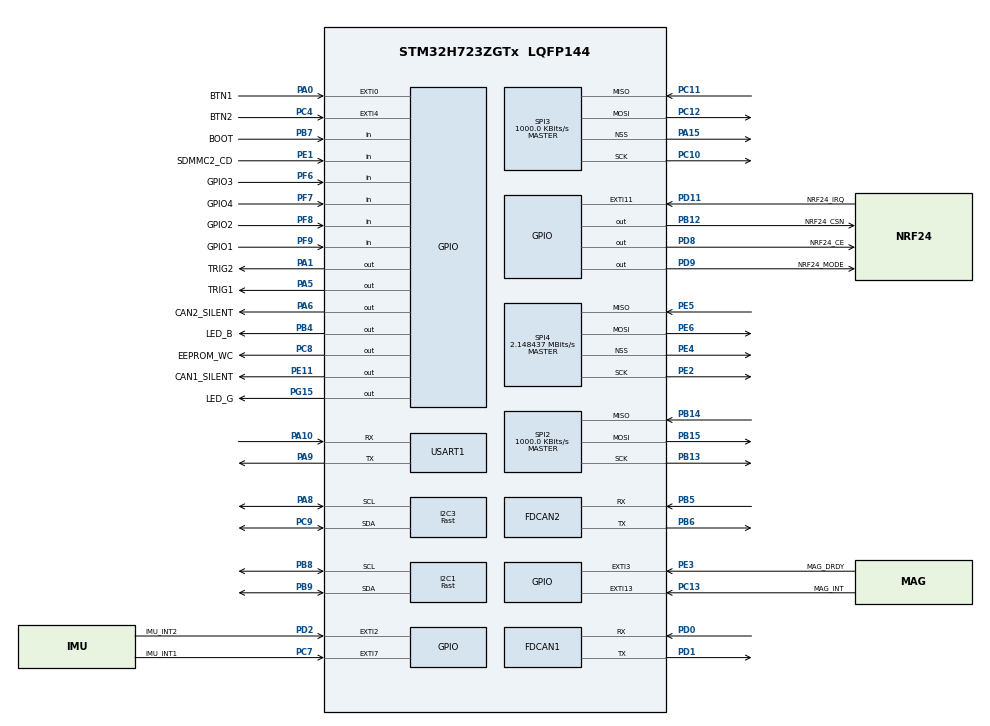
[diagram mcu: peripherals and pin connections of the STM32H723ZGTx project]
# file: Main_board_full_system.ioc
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CORTEX_M7.CPU_DCache=Enabled
CORTEX_M7.CPU_ICache=Enabled
CORTEX_M7.default_mode_Activation=1
FDCAN1.CalculateBaudRateNominal=1250000
FDCAN1.CalculateTimeBitNominal=800
FDCAN1.CalculateTimeQuantumNominal=160.0
FDCAN2.CalculateBaudRateNominal=125000
FDCAN2.CalculateTimeBitNominal=8000
FDCAN2.CalculateTimeQuantumNominal=500.0
FDCAN2.NominalPrescaler=50
FDCAN2.NominalTimeSeg1=13
FREERTOS.Tasks01=debugTask,24,512,startDebugTask,Default,NULL,Static,debugTaskBuffer,debugTaskControlBlock;radioTask,32,512,startRadioTask,As external,NULL,Static,radioTaskBuffer,radioTaskControlBlock;motorTask,40,512,startMotorTask,As external,NULL,Static,motorTaskBuffer,motorTaskControlBlock;sensorsTask,8,512,startSensorsTask,As external,NULL,Static,sensorsTaskBuffer,sensorsTaskControlBlock
FREERTOS.configMINIMAL_STACK_SIZE=512
FREERTOS.configUSE_NEWLIB_REENTRANT=1
I2C1.CustomTiming=Enabled
I2C1.I2C_Speed_Mode=I2C_Fast
I2C1.Speed=100
I2C1.Timing=0x60100AB6
I2C3.I2C_Speed_Mode=I2C_Fast
I2C3.Timing=0x60100AB6
Mcu.Family=STM32H7
Mcu.Name=STM32H723ZGTx
Mcu.Package=LQFP144
NVIC.FDCAN1_IT0_IRQn=true\:5\:0\:false\:false\:true\:true\:true\:true\:true
NVIC.FDCAN1_IT1_IRQn=true\:5\:0\:false\:false\:true\:true\:true\:true\:true
NVIC.FDCAN2_IT0_IRQn=true\:5\:0\:false\:false\:true\:true\:true\:true\:true
NVIC.FDCAN2_IT1_IRQn=true\:5\:0\:false\:false\:true\:true\:true\:true\:true
NVIC.I2C1_EV_IRQn=true\:5\:0\:false\:false\:true\:true\:true\:true\:true
NVIC.I2C3_EV_IRQn=true\:5\:0\:false\:false\:true\:true\:true\:true\:true
NVIC.PriorityGroup=NVIC_PRIORITYGROUP_4
NVIC.SPI2_IRQn=true\:5\:0\:false\:false\:true\:true\:true\:true\:true
NVIC.SPI3_IRQn=true\:5\:0\:false\:false\:true\:true\:true\:true\:true
NVIC.SPI4_IRQn=true\:5\:0\:false\:false\:true\:true\:true\:true\:true
NVIC.TIM6_DAC_IRQn=true\:15\:0\:false\:false\:true\:false\:false\:true\:true
NVIC.TimeBase=TIM6_DAC_IRQn
NVIC.TimeBaseIP=TIM6
NVIC.USART1_IRQn=true\:5\:0\:false\:false\:true\:true\:true\:true\:true
PA0.GPIO_Label=BTN1
PA0.Signal=GPXTI0
PA1.GPIO_Label=TRIG2
PA1.Signal=GPIO_Output
PA10.Mode=Asynchronous
PA10.Signal=USART1_RX
PA11.Signal=USB_OTG_HS_DM
PA12.Signal=USB_OTG_HS_DP
PA13(JTMS/SWDIO).Mode=Trace_Asynchronous_SW
PA13(JTMS/SWDIO).Signal=DEBUG_JTMS-SWDIO
PA14(JTCK/SWCLK).Mode=Trace_Asynchronous_SW
PA14(JTCK/SWCLK).Signal=DEBUG_JTCK-SWCLK
PA15(JTDI).Mode=NSS_Signal_Hard_Output
PA15(JTDI).Signal=SPI3_NSS
PA5.GPIO_Label=TRIG1
PA5.Signal=GPIO_Output
PA6.GPIO_Label=CAN2_SILENT
PA6.GPIO_PuPd=GPIO_PULLUP
PA6.Signal=GPIO_Output
PA8.Mode=I2C
PA8.Signal=I2C3_SCL
PA9.Mode=Asynchronous
PA9.Signal=USART1_TX
PB12.GPIO_Label=NRF24_CSN
PB12.Signal=GPIO_Output
PB13.Mode=Full_Duplex_Master
PB13.Signal=SPI2_SCK
PB14.Mode=Full_Duplex_Master
PB14.Signal=SPI2_MISO
PB15.Mode=Full_Duplex_Master
PB15.Signal=SPI2_MOSI
PB3(JTDO/TRACESWO).Mode=Trace_Asynchronous_SW
PB3(JTDO/TRACESWO).Signal=DEBUG_JTDO-SWO
PB4(NJTRST).GPIO_Label=LED_B
PB4(NJTRST).Signal=GPIO_Output
PB5.Mode=FDCAN_Activate
PB5.Signal=FDCAN2_RX
PB6.Mode=FDCAN_Activate
PB6.Signal=FDCAN2_TX
PB7.GPIO_Label=BOOT
PB7.Signal=GPIO_Input
PB8.Mode=I2C
PB8.Signal=I2C1_SCL
PB9.Mode=I2C
PB9.Signal=I2C1_SDA
PC10.Mode=Full_Duplex_Master
PC10.Signal=SPI3_SCK
PC11.Mode=Full_Duplex_Master
PC11.Signal=SPI3_MISO
PC12.Mode=Full_Duplex_Master
PC12.Signal=SPI3_MOSI
PC13.GPIO_Label=MAG_INT
PC13.Signal=GPXTI13
PC14-OSC32_IN.Mode=LSE-External-Clock-Source
PC14-OSC32_IN.Signal=RCC_OSC32_IN
PC4.GPIO_Label=BTN2
PC4.Signal=GPXTI4
PC7.GPIO_Label=IMU_INT1
PC7.Signal=GPXTI7
PC8.GPIO_Label=EEPROM_WC
PC8.GPIO_PuPd=GPIO_PULLUP
PC8.Signal=GPIO_Output
PC9.Mode=I2C
PC9.Signal=I2C3_SDA
PD0.Mode=FDCAN_Activate
PD0.Signal=FDCAN1_RX
PD1.Mode=FDCAN_Activate
PD1.Signal=FDCAN1_TX
PD11.GPIO_Label=NRF24_IRQ
PD11.Signal=GPXTI11
PD2.GPIO_Label=IMU_INT2
PD2.Signal=GPXTI2
PD6.Signal=SDMMC2_CK
PD7.Signal=SDMMC2_CMD
PD8.GPIO_Label=NRF24_CE
PD8.Signal=GPIO_Output
PD9.GPIO_Label=NRF24_MODE
PD9.Signal=GPIO_Output
PE1.GPIO_Label=SDMMC2_CD
PE1.Signal=GPIO_Input
PE11.GPIO_Label=CAN1_SILENT
PE11.GPIO_PuPd=GPIO_PULLUP
PE11.Signal=GPIO_Output
PE2.Mode=Full_Duplex_Master
PE2.Signal=SPI4_SCK
PE3.GPIO_Label=MAG_DRDY
PE3.Signal=GPXTI3
PE4.Mode=NSS_Signal_Hard_Output
PE4.Signal=SPI4_NSS
PE5.Mode=Full_Duplex_Master
PE5.Signal=SPI4_MISO
PE6.Mode=Full_Duplex_Master
PE6.Signal=SPI4_MOSI
PF6.GPIO_Label=GPIO3
PF6.Signal=GPIO_Input
PF7.GPIO_Label=GPIO4
PF7.Signal=GPIO_Input
PF8.GPIO_Label=GPIO2
PF8.Signal=GPIO_Input
PF9.GPIO_Label=GPIO1
PF9.Signal=GPIO_Input
PG10.Signal=SDMMC2_D1
PG11.Signal=SDMMC2_D2
PG12.Signal=SDMMC2_D3
PG15.GPIO_Label=LED_G
PG15.Signal=GPIO_Output
PG9.Signal=SDMMC2_D0
PH0-OSC_IN.Mode=HSE-External-Clock-Source
PH0-OSC_IN.Signal=RCC_OSC_IN
ProjectManager.HeapSize=0x200
ProjectManager.StackSize=0x400
ProjectManager.TargetToolchain=STM32CubeIDE
RCC.ADCFreq_Value=100000000
RCC.APB1Freq_Value=137500000
RCC.APB2Freq_Value=137500000
RCC.APB3Freq_Value=137500000
RCC.APB4Freq_Value=137500000
RCC.CortexFreq_Value=550000000
RCC.D1PPRE=RCC_APB3_DIV2
RCC.D2PPRE1=RCC_APB1_DIV2
RCC.D2PPRE2=RCC_APB2_DIV2
RCC.D3PPRE=RCC_APB4_DIV2
RCC.DIVM1=2
RCC.DIVM2=2
RCC.DIVM3=5
RCC.DIVN1=44
RCC.DIVN2=16
RCC.DIVN3=64
RCC.DIVP1=1
RCC.DIVP3=5
RCC.DIVQ1=5
RCC.FDCANCLockSelection=RCC_FDCANCLKSOURCE_PLL2
RCC.HCLKFreq_Value=275000000
RCC.HPRE=RCC_HCLK_DIV2
RCC.PLL3FRACN=0
RCC.PLLFRACN=0
RCC.PLLSourceVirtual=RCC_PLLSOURCE_HSE
RCC.SPI123CLockSelection=RCC_SPI123CLKSOURCE_PLL3
RCC.SYSCLKFreq_VALUE=550000000
RCC.SYSCLKSource=RCC_SYSCLKSOURCE_PLLCLK
RCC.USBFreq_Value=110000000
SPI2.BaudRatePrescaler=SPI_BAUDRATEPRESCALER_64
SPI2.CalculateBaudRate=1000.0 KBits/s
SPI2.DataSize=SPI_DATASIZE_8BIT
SPI2.Direction=SPI_DIRECTION_2LINES
SPI2.Mode=SPI_MODE_MASTER
SPI2.VirtualType=VM_MASTER
SPI3.BaudRatePrescaler=SPI_BAUDRATEPRESCALER_64
SPI3.CalculateBaudRate=1000.0 KBits/s
SPI3.DataSize=SPI_DATASIZE_8BIT
SPI3.Direction=SPI_DIRECTION_2LINES
SPI3.Mode=SPI_MODE_MASTER
SPI3.VirtualNSS=VM_NSSHARD
SPI3.VirtualType=VM_MASTER
SPI4.BaudRatePrescaler=SPI_BAUDRATEPRESCALER_64
SPI4.CalculateBaudRate=2.148437 MBits/s
SPI4.DataSize=SPI_DATASIZE_8BIT
SPI4.Direction=SPI_DIRECTION_2LINES
SPI4.Mode=SPI_MODE_MASTER
SPI4.VirtualNSS=VM_NSSHARD
SPI4.VirtualType=VM_MASTER
USART1.VirtualMode-Asynchronous=VM_ASYNC
VP_CRC_VS_CRC.Mode=CRC_Activate
VP_FREERTOS_VS_CMSIS_V2.Mode=CMSIS_V2
VP_RCC_LSE.Mode=CRS SYNC Source LSE
VP_SYS_VS_tim6.Mode=TIM6
board=custom

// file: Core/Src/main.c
/* USER CODE BEGIN Header */
/**
  ******************************************************************************
  * @file           : main.c
  * @brief          : Main program body
  ******************************************************************************
  * @attention
  *
  * Copyright (c) 2024 STMicroelectronics.
  * All rights reserved.
  *
  * This software is licensed under terms that can be found in the LICENSE file
  * in the root directory of this software component.
  * If no LICENSE file comes with this software, it is provided AS-IS.
  *
  ******************************************************************************
  */
/* USER CODE END Header */
#include "main.h"
#include "cmsis_os.h"

/* USER CODE BEGIN Includes */
#include "tasks.h"
/* USER CODE END Includes */

typedef StaticTask_t osStaticThreadDef_t;

CRC_HandleTypeDef hcrc;

FDCAN_HandleTypeDef hfdcan1;
FDCAN_HandleTypeDef hfdcan2;

I2C_HandleTypeDef hi2c1;
I2C_HandleTypeDef hi2c3;

SPI_HandleTypeDef hspi2;
SPI_HandleTypeDef hspi3;
SPI_HandleTypeDef hspi4;

UART_HandleTypeDef huart1;

/* Definitions for debugTask */
osThreadId_t debugTaskHandle;
uint32_t debugTaskBuffer[ 512 ];
osStaticThreadDef_t debugTaskControlBlock;
const osThreadAttr_t debugTask_attributes = {
  .name = "debugTask",
  .cb_mem = &debugTaskControlBlock,
  .cb_size = sizeof(debugTaskControlBlock),
  .stack_mem = &debugTaskBuffer[0],
  .stack_size = sizeof(debugTaskBuffer),
  .priority = (osPriority_t) osPriorityNormal,
};
/* Definitions for radioTask */
osThreadId_t radioTaskHandle;
uint32_t radioTaskBuffer[ 512 ];
osStaticThreadDef_t radioTaskControlBlock;
const osThreadAttr_t radioTask_attributes = {
  .name = "radioTask",
  .cb_mem = &radioTaskControlBlock,
  .cb_size = sizeof(radioTaskControlBlock),
  .stack_mem = &radioTaskBuffer[0],
  .stack_size = sizeof(radioTaskBuffer),
  .priority = (osPriority_t) osPriorityAboveNormal,
};
/* Definitions for motorTask */
osThreadId_t motorTaskHandle;
uint32_t motorTaskBuffer[ 512 ];
osStaticThreadDef_t motorTaskControlBlock;
const osThreadAttr_t motorTask_attributes = {
  .name = "motorTask",
  .cb_mem = &motorTaskControlBlock,
  .cb_size = sizeof(motorTaskControlBlock),
  .stack_mem = &motorTaskBuffer[0],
  .stack_size = sizeof(motorTaskBuffer),
  .priority = (osPriority_t) osPriorityHigh,
};
/* Definitions for sensorsTask */
osThreadId_t sensorsTaskHandle;
uint32_t sensorsTaskBuffer[ 512 ];
osStaticThreadDef_t sensorsTaskControlBlock;
const osThreadAttr_t sensorsTask_attributes = {
  .name = "sensorsTask",
  .cb_mem = &sensorsTaskControlBlock,
  .cb_size = sizeof(sensorsTaskControlBlock),
  .stack_mem = &sensorsTaskBuffer[0],
  .stack_size = sizeof(sensorsTaskBuffer),
  .priority = (osPriority_t) osPriorityLow,
};

void SystemClock_Config(void);
void PeriphCommonClock_Config(void);
static void MPU_Config(void);
static void MX_GPIO_Init(void);
static void MX_FDCAN1_Init(void);
static void MX_FDCAN2_Init(void);
static void MX_I2C1_Init(void);
static void MX_I2C3_Init(void);
static void MX_SPI2_Init(void);
static void MX_SPI3_Init(void);
static void MX_SPI4_Init(void);
static void MX_USART1_UART_Init(void);
static void MX_CRC_Init(void);
void startDebugTask(void *argument);
extern void startRadioTask(void *argument);
extern void startMotorTask(void *argument);
extern void startSensorsTask(void *argument);

int main(void)
{

  /* MPU Configuration--------------------------------------------------------*/
  MPU_Config();
/* Enable the CPU Cache */

  /* Enable I-Cache---------------------------------------------------------*/
  SCB_EnableICache();

  /* Enable D-Cache---------------------------------------------------------*/
  SCB_EnableDCache();

  /* MCU Configuration--------------------------------------------------------*/

  /* Reset of all peripherals, Initializes the Flash interface and the Systick. */
  HAL_Init();

  /* Configure the system clock */
  SystemClock_Config();

/* Configure the peripherals common clocks */
  PeriphCommonClock_Config();

  /* Initialize all configured peripherals */
  MX_GPIO_Init();
  MX_FDCAN1_Init();
  MX_FDCAN2_Init();
  MX_I2C1_Init();
  MX_I2C3_Init();
  MX_SPI2_Init();
  MX_SPI3_Init();
  MX_SPI4_Init();
  MX_USART1_UART_Init();
  MX_CRC_Init();

  /* Init scheduler */
  osKernelInitialize();

  /* Create the thread(s) */
  /* creation of debugTask */
  debugTaskHandle = osThreadNew(startDebugTask, NULL, &debugTask_attributes);

  /* creation of radioTask */
  radioTaskHandle = osThreadNew(startRadioTask, NULL, &radioTask_attributes);

  /* creation of motorTask */
  motorTaskHandle = osThreadNew(startMotorTask, NULL, &motorTask_attributes);

  /* creation of sensorsTask */
  sensorsTaskHandle = osThreadNew(startSensorsTask, NULL, &sensorsTask_attributes);

  /* Start scheduler */
  osKernelStart();

  /* We should never get here as control is now taken by the scheduler */
  /* Infinite loop */
  while (1)
  {

  }
}

void SystemClock_Config(void)
{
  RCC_OscInitTypeDef RCC_OscInitStruct = {0};
  RCC_ClkInitTypeDef RCC_ClkInitStruct = {0};
  RCC_CRSInitTypeDef RCC_CRSInitStruct = {0};

  /** Supply configuration update enable
  */
  HAL_PWREx_ConfigSupply(PWR_LDO_SUPPLY);

  /** Configure the main internal regulator output voltage
  */
  __HAL_PWR_VOLTAGESCALING_CONFIG(PWR_REGULATOR_VOLTAGE_SCALE0);

  while(!__HAL_PWR_GET_FLAG(PWR_FLAG_VOSRDY)) {}

  /** Initializes the RCC Oscillators according to the specified parameters
  * in the RCC_OscInitTypeDef structure.
  */
  RCC_OscInitStruct.OscillatorType = RCC_OSCILLATORTYPE_HSI48|RCC_OSCILLATORTYPE_HSE
                              |RCC_OSCILLATORTYPE_LSE;
  RCC_OscInitStruct.HSEState = RCC_HSE_BYPASS;
  RCC_OscInitStruct.LSEState = RCC_LSE_BYPASS;
  RCC_OscInitStruct.HSI48State = RCC_HSI48_ON;
  RCC_OscInitStruct.PLL.PLLState = RCC_PLL_ON;
  RCC_OscInitStruct.PLL.PLLSource = RCC_PLLSOURCE_HSE;
  RCC_OscInitStruct.PLL.PLLM = 2;
  RCC_OscInitStruct.PLL.PLLN = 44;
  RCC_OscInitStruct.PLL.PLLP = 1;
  RCC_OscInitStruct.PLL.PLLQ = 5;
  RCC_OscInitStruct.PLL.PLLR = 2;
  RCC_OscInitStruct.PLL.PLLRGE = RCC_PLL1VCIRANGE_3;
  RCC_OscInitStruct.PLL.PLLVCOSEL = RCC_PLL1VCOWIDE;
  RCC_OscInitStruct.PLL.PLLFRACN = 0;
  if (HAL_RCC_OscConfig(&RCC_OscInitStruct) != HAL_OK)
  {
    Error_Handler();
  }

  /** Initializes the CPU, AHB and APB buses clocks
  */
  RCC_ClkInitStruct.ClockType = RCC_CLOCKTYPE_HCLK|RCC_CLOCKTYPE_SYSCLK
                              |RCC_CLOCKTYPE_PCLK1|RCC_CLOCKTYPE_PCLK2
                              |RCC_CLOCKTYPE_D3PCLK1|RCC_CLOCKTYPE_D1PCLK1;
  RCC_ClkInitStruct.SYSCLKSource = RCC_SYSCLKSOURCE_PLLCLK;
  RCC_ClkInitStruct.SYSCLKDivider = RCC_SYSCLK_DIV1;
  RCC_ClkInitStruct.AHBCLKDivider = RCC_HCLK_DIV2;
  RCC_ClkInitStruct.APB3CLKDivider = RCC_APB3_DIV2;
  RCC_ClkInitStruct.APB1CLKDivider = RCC_APB1_DIV2;
  RCC_ClkInitStruct.APB2CLKDivider = RCC_APB2_DIV2;
  RCC_ClkInitStruct.APB4CLKDivider = RCC_APB4_DIV2;

  if (HAL_RCC_ClockConfig(&RCC_ClkInitStruct, FLASH_LATENCY_3) != HAL_OK)
  {
    Error_Handler();
  }

  /** Enable the SYSCFG APB clock
  */
  __HAL_RCC_CRS_CLK_ENABLE();

  /** Configures CRS
  */
  RCC_CRSInitStruct.Prescaler = RCC_CRS_SYNC_DIV1;
  RCC_CRSInitStruct.Source = RCC_CRS_SYNC_SOURCE_LSE;
  RCC_CRSInitStruct.Polarity = RCC_CRS_SYNC_POLARITY_RISING;
  RCC_CRSInitStruct.ReloadValue = __HAL_RCC_CRS_RELOADVALUE_CALCULATE(48000000,32768);
  RCC_CRSInitStruct.ErrorLimitValue = 34;
  RCC_CRSInitStruct.HSI48CalibrationValue = 32;

  HAL_RCCEx_CRSConfig(&RCC_CRSInitStruct);
}

void PeriphCommonClock_Config(void)
{
  RCC_PeriphCLKInitTypeDef PeriphClkInitStruct = {0};

  /** Initializes the peripherals clock
  */
  PeriphClkInitStruct.PeriphClockSelection = RCC_PERIPHCLK_SPI3|RCC_PERIPHCLK_SPI2
                              |RCC_PERIPHCLK_FDCAN;
  PeriphClkInitStruct.PLL2.PLL2M = 2;
  PeriphClkInitStruct.PLL2.PLL2N = 16;
  PeriphClkInitStruct.PLL2.PLL2P = 2;
  PeriphClkInitStruct.PLL2.PLL2Q = 2;
  PeriphClkInitStruct.PLL2.PLL2R = 2;
  PeriphClkInitStruct.PLL2.PLL2RGE = RCC_PLL2VCIRANGE_3;
  PeriphClkInitStruct.PLL2.PLL2VCOSEL = RCC_PLL2VCOWIDE;
  PeriphClkInitStruct.PLL2.PLL2FRACN = 0;
  PeriphClkInitStruct.PLL3.PLL3M = 5;
  PeriphClkInitStruct.PLL3.PLL3N = 64;
  PeriphClkInitStruct.PLL3.PLL3P = 5;
  PeriphClkInitStruct.PLL3.PLL3Q = 2;
  PeriphClkInitStruct.PLL3.PLL3R = 2;
  PeriphClkInitStruct.PLL3.PLL3RGE = RCC_PLL3VCIRANGE_2;
  PeriphClkInitStruct.PLL3.PLL3VCOSEL = RCC_PLL3VCOWIDE;
  PeriphClkInitStruct.PLL3.PLL3FRACN = 0;
  PeriphClkInitStruct.Spi123ClockSelection = RCC_SPI123CLKSOURCE_PLL3;
  PeriphClkInitStruct.FdcanClockSelection = RCC_FDCANCLKSOURCE_PLL2;
  if (HAL_RCCEx_PeriphCLKConfig(&PeriphClkInitStruct) != HAL_OK)
  {
    Error_Handler();
  }
}

static void MX_CRC_Init(void)
{

  hcrc.Instance = CRC;
  hcrc.Init.DefaultPolynomialUse = DEFAULT_POLYNOMIAL_ENABLE;
  hcrc.Init.DefaultInitValueUse = DEFAULT_INIT_VALUE_ENABLE;
  hcrc.Init.InputDataInversionMode = CRC_INPUTDATA_INVERSION_NONE;
  hcrc.Init.OutputDataInversionMode = CRC_OUTPUTDATA_INVERSION_DISABLE;
  hcrc.InputDataFormat = CRC_INPUTDATA_FORMAT_BYTES;
  if (HAL_CRC_Init(&hcrc) != HAL_OK)
  {
    Error_Handler();
  }

}

static void MX_FDCAN1_Init(void)
{

  hfdcan1.Instance = FDCAN1;
  hfdcan1.Init.FrameFormat = FDCAN_FRAME_CLASSIC;
  hfdcan1.Init.Mode = FDCAN_MODE_NORMAL;
  hfdcan1.Init.AutoRetransmission = DISABLE;
  hfdcan1.Init.TransmitPause = DISABLE;
  hfdcan1.Init.ProtocolException = DISABLE;
  hfdcan1.Init.NominalPrescaler = 16;
  hfdcan1.Init.NominalSyncJumpWidth = 1;
  hfdcan1.Init.NominalTimeSeg1 = 2;
  hfdcan1.Init.NominalTimeSeg2 = 2;
  hfdcan1.Init.DataPrescaler = 1;
  hfdcan1.Init.DataSyncJumpWidth = 1;
  hfdcan1.Init.DataTimeSeg1 = 1;
  hfdcan1.Init.DataTimeSeg2 = 1;
  hfdcan1.Init.MessageRAMOffset = 0;
  hfdcan1.Init.StdFiltersNbr = 0;
  hfdcan1.Init.ExtFiltersNbr = 0;
  hfdcan1.Init.RxFifo0ElmtsNbr = 0;
  hfdcan1.Init.RxFifo0ElmtSize = FDCAN_DATA_BYTES_8;
  hfdcan1.Init.RxFifo1ElmtsNbr = 0;
  hfdcan1.Init.RxFifo1ElmtSize = FDCAN_DATA_BYTES_8;
  hfdcan1.Init.RxBuffersNbr = 0;
  hfdcan1.Init.RxBufferSize = FDCAN_DATA_BYTES_8;
  hfdcan1.Init.TxEventsNbr = 0;
  hfdcan1.Init.TxBuffersNbr = 0;
  hfdcan1.Init.TxFifoQueueElmtsNbr = 0;
  hfdcan1.Init.TxFifoQueueMode = FDCAN_TX_FIFO_OPERATION;
  hfdcan1.Init.TxElmtSize = FDCAN_DATA_BYTES_8;
  if (HAL_FDCAN_Init(&hfdcan1) != HAL_OK)
  {
    Error_Handler();
  }

}

static void MX_FDCAN2_Init(void)
{

  hfdcan2.Instance = FDCAN2;
  hfdcan2.Init.FrameFormat = FDCAN_FRAME_CLASSIC;
  hfdcan2.Init.Mode = FDCAN_MODE_NORMAL;
  hfdcan2.Init.AutoRetransmission = DISABLE;
  hfdcan2.Init.TransmitPause = DISABLE;
  hfdcan2.Init.ProtocolException = DISABLE;
  hfdcan2.Init.NominalPrescaler = 50;
  hfdcan2.Init.NominalSyncJumpWidth = 1;
  hfdcan2.Init.NominalTimeSeg1 = 13;
  hfdcan2.Init.NominalTimeSeg2 = 2;
  hfdcan2.Init.DataPrescaler = 1;
  hfdcan2.Init.DataSyncJumpWidth = 1;
  hfdcan2.Init.DataTimeSeg1 = 1;
  hfdcan2.Init.DataTimeSeg2 = 1;
  hfdcan2.Init.MessageRAMOffset = 0;
  hfdcan2.Init.StdFiltersNbr = 0;
  hfdcan2.Init.ExtFiltersNbr = 0;
  hfdcan2.Init.RxFifo0ElmtsNbr = 0;
  hfdcan2.Init.RxFifo0ElmtSize = FDCAN_DATA_BYTES_8;
  hfdcan2.Init.RxFifo1ElmtsNbr = 0;
  hfdcan2.Init.RxFifo1ElmtSize = FDCAN_DATA_BYTES_8;
  hfdcan2.Init.RxBuffersNbr = 0;
  hfdcan2.Init.RxBufferSize = FDCAN_DATA_BYTES_8;
  hfdcan2.Init.TxEventsNbr = 0;
  hfdcan2.Init.TxBuffersNbr = 0;
  hfdcan2.Init.TxFifoQueueElmtsNbr = 0;
  hfdcan2.Init.TxFifoQueueMode = FDCAN_TX_FIFO_OPERATION;
  hfdcan2.Init.TxElmtSize = FDCAN_DATA_BYTES_8;
  if (HAL_FDCAN_Init(&hfdcan2) != HAL_OK)
  {
    Error_Handler();
  }

}

static void MX_I2C1_Init(void)
{

  hi2c1.Instance = I2C1;
  hi2c1.Init.Timing = 0x60100AB6;
  hi2c1.Init.OwnAddress1 = 0;
  hi2c1.Init.AddressingMode = I2C_ADDRESSINGMODE_7BIT;
  hi2c1.Init.DualAddressMode = I2C_DUALADDRESS_DISABLE;
  hi2c1.Init.OwnAddress2 = 0;
  hi2c1.Init.OwnAddress2Masks = I2C_OA2_NOMASK;
  hi2c1.Init.GeneralCallMode = I2C_GENERALCALL_DISABLE;
  hi2c1.Init.NoStretchMode = I2C_NOSTRETCH_DISABLE;
  if (HAL_I2C_Init(&hi2c1) != HAL_OK)
  {
    Error_Handler();
  }

  /** Configure Analogue filter
  */
  if (HAL_I2CEx_ConfigAnalogFilter(&hi2c1, I2C_ANALOGFILTER_ENABLE) != HAL_OK)
  {
    Error_Handler();
  }

  /** Configure Digital filter
  */
  if (HAL_I2CEx_ConfigDigitalFilter(&hi2c1, 0) != HAL_OK)
  {
    Error_Handler();
  }

}

static void MX_I2C3_Init(void)
{

  hi2c3.Instance = I2C3;
  hi2c3.Init.Timing = 0x60100AB6;
  hi2c3.Init.OwnAddress1 = 0;
  hi2c3.Init.AddressingMode = I2C_ADDRESSINGMODE_7BIT;
  hi2c3.Init.DualAddressMode = I2C_DUALADDRESS_DISABLE;
  hi2c3.Init.OwnAddress2 = 0;
  hi2c3.Init.OwnAddress2Masks = I2C_OA2_NOMASK;
  hi2c3.Init.GeneralCallMode = I2C_GENERALCALL_DISABLE;
  hi2c3.Init.NoStretchMode = I2C_NOSTRETCH_DISABLE;
  if (HAL_I2C_Init(&hi2c3) != HAL_OK)
  {
    Error_Handler();
  }

  /** Configure Analogue filter
  */
  if (HAL_I2CEx_ConfigAnalogFilter(&hi2c3, I2C_ANALOGFILTER_ENABLE) != HAL_OK)
  {
    Error_Handler();
  }

  /** Configure Digital filter
  */
  if (HAL_I2CEx_ConfigDigitalFilter(&hi2c3, 0) != HAL_OK)
  {
    Error_Handler();
  }

}

static void MX_SPI2_Init(void)
{

  /* SPI2 parameter configuration*/
  hspi2.Instance = SPI2;
  hspi2.Init.Mode = SPI_MODE_MASTER;
  hspi2.Init.Direction = SPI_DIRECTION_2LINES;
  hspi2.Init.DataSize = SPI_DATASIZE_8BIT;
  hspi2.Init.CLKPolarity = SPI_POLARITY_LOW;
  hspi2.Init.CLKPhase = SPI_PHASE_1EDGE;
  hspi2.Init.NSS = SPI_NSS_SOFT;
  hspi2.Init.BaudRatePrescaler = SPI_BAUDRATEPRESCALER_64;
  hspi2.Init.FirstBit = SPI_FIRSTBIT_MSB;
  hspi2.Init.TIMode = SPI_TIMODE_DISABLE;
  hspi2.Init.CRCCalculation = SPI_CRCCALCULATION_DISABLE;
  hspi2.Init.CRCPolynomial = 0x0;
  hspi2.Init.NSSPMode = SPI_NSS_PULSE_ENABLE;
  hspi2.Init.NSSPolarity = SPI_NSS_POLARITY_LOW;
  hspi2.Init.FifoThreshold = SPI_FIFO_THRESHOLD_01DATA;
  hspi2.Init.TxCRCInitializationPattern = SPI_CRC_INITIALIZATION_ALL_ZERO_PATTERN;
  hspi2.Init.RxCRCInitializationPattern = SPI_CRC_INITIALIZATION_ALL_ZERO_PATTERN;
  hspi2.Init.MasterSSIdleness = SPI_MASTER_SS_IDLENESS_00CYCLE;
  hspi2.Init.MasterInterDataIdleness = SPI_MASTER_INTERDATA_IDLENESS_00CYCLE;
  hspi2.Init.MasterReceiverAutoSusp = SPI_MASTER_RX_AUTOSUSP_DISABLE;
  hspi2.Init.MasterKeepIOState = SPI_MASTER_KEEP_IO_STATE_DISABLE;
  hspi2.Init.IOSwap = SPI_IO_SWAP_DISABLE;
  if (HAL_SPI_Init(&hspi2) != HAL_OK)
  {
    Error_Handler();
  }

}

static void MX_SPI3_Init(void)
{

  /* SPI3 parameter configuration*/
  hspi3.Instance = SPI3;
  hspi3.Init.Mode = SPI_MODE_MASTER;
  hspi3.Init.Direction = SPI_DIRECTION_2LINES;
  hspi3.Init.DataSize = SPI_DATASIZE_8BIT;
  hspi3.Init.CLKPolarity = SPI_POLARITY_LOW;
  hspi3.Init.CLKPhase = SPI_PHASE_1EDGE;
  hspi3.Init.NSS = SPI_NSS_HARD_OUTPUT;
  hspi3.Init.BaudRatePrescaler = SPI_BAUDRATEPRESCALER_64;
  hspi3.Init.FirstBit = SPI_FIRSTBIT_MSB;
  hspi3.Init.TIMode = SPI_TIMODE_DISABLE;
  hspi3.Init.CRCCalculation = SPI_CRCCALCULATION_DISABLE;
  hspi3.Init.CRCPolynomial = 0x0;
  hspi3.Init.NSSPMode = SPI_NSS_PULSE_ENABLE;
  hspi3.Init.NSSPolarity = SPI_NSS_POLARITY_LOW;
  hspi3.Init.FifoThreshold = SPI_FIFO_THRESHOLD_01DATA;
  hspi3.Init.TxCRCInitializationPattern = SPI_CRC_INITIALIZATION_ALL_ZERO_PATTERN;
  hspi3.Init.RxCRCInitializationPattern = SPI_CRC_INITIALIZATION_ALL_ZERO_PATTERN;
  hspi3.Init.MasterSSIdleness = SPI_MASTER_SS_IDLENESS_00CYCLE;
  hspi3.Init.MasterInterDataIdleness = SPI_MASTER_INTERDATA_IDLENESS_00CYCLE;
  hspi3.Init.MasterReceiverAutoSusp = SPI_MASTER_RX_AUTOSUSP_DISABLE;
  hspi3.Init.MasterKeepIOState = SPI_MASTER_KEEP_IO_STATE_DISABLE;
  hspi3.Init.IOSwap = SPI_IO_SWAP_DISABLE;
  if (HAL_SPI_Init(&hspi3) != HAL_OK)
  {
    Error_Handler();
  }

}

static void MX_SPI4_Init(void)
{

  /* SPI4 parameter configuration*/
  hspi4.Instance = SPI4;
  hspi4.Init.Mode = SPI_MODE_MASTER;
  hspi4.Init.Direction = SPI_DIRECTION_2LINES;
  hspi4.Init.DataSize = SPI_DATASIZE_8BIT;
  hspi4.Init.CLKPolarity = SPI_POLARITY_LOW;
  hspi4.Init.CLKPhase = SPI_PHASE_1EDGE;
  hspi4.Init.NSS = SPI_NSS_HARD_OUTPUT;
  hspi4.Init.BaudRatePrescaler = SPI_BAUDRATEPRESCALER_64;
  hspi4.Init.FirstBit = SPI_FIRSTBIT_MSB;
  hspi4.Init.TIMode = SPI_TIMODE_DISABLE;
  hspi4.Init.CRCCalculation = SPI_CRCCALCULATION_DISABLE;
  hspi4.Init.CRCPolynomial = 0x0;
  hspi4.Init.NSSPMode = SPI_NSS_PULSE_ENABLE;
  hspi4.Init.NSSPolarity = SPI_NSS_POLARITY_LOW;
  hspi4.Init.FifoThreshold = SPI_FIFO_THRESHOLD_01DATA;
  hspi4.Init.TxCRCInitializationPattern = SPI_CRC_INITIALIZATION_ALL_ZERO_PATTERN;
  hspi4.Init.RxCRCInitializationPattern = SPI_CRC_INITIALIZATION_ALL_ZERO_PATTERN;
  hspi4.Init.MasterSSIdleness = SPI_MASTER_SS_IDLENESS_00CYCLE;
  hspi4.Init.MasterInterDataIdleness = SPI_MASTER_INTERDATA_IDLENESS_00CYCLE;
  hspi4.Init.MasterReceiverAutoSusp = SPI_MASTER_RX_AUTOSUSP_DISABLE;
  hspi4.Init.MasterKeepIOState = SPI_MASTER_KEEP_IO_STATE_DISABLE;
  hspi4.Init.IOSwap = SPI_IO_SWAP_DISABLE;
  if (HAL_SPI_Init(&hspi4) != HAL_OK)
  {
    Error_Handler();
  }

}

static void MX_USART1_UART_Init(void)
{

  huart1.Instance = USART1;
  huart1.Init.BaudRate = 115200;
  huart1.Init.WordLength = UART_WORDLENGTH_8B;
  huart1.Init.StopBits = UART_STOPBITS_1;
  huart1.Init.Parity = UART_PARITY_NONE;
  huart1.Init.Mode = UART_MODE_TX_RX;
  huart1.Init.HwFlowCtl = UART_HWCONTROL_NONE;
  huart1.Init.OverSampling = UART_OVERSAMPLING_16;
  huart1.Init.OneBitSampling = UART_ONE_BIT_SAMPLE_DISABLE;
  huart1.Init.ClockPrescaler = UART_PRESCALER_DIV1;
  huart1.AdvancedInit.AdvFeatureInit = UART_ADVFEATURE_NO_INIT;
  if (HAL_UART_Init(&huart1) != HAL_OK)
  {
    Error_Handler();
  }
  if (HAL_UARTEx_SetTxFifoThreshold(&huart1, UART_TXFIFO_THRESHOLD_1_8) != HAL_OK)
  {
    Error_Handler();
  }
  if (HAL_UARTEx_SetRxFifoThreshold(&huart1, UART_RXFIFO_THRESHOLD_1_8) != HAL_OK)
  {
    Error_Handler();
  }
  if (HAL_UARTEx_DisableFifoMode(&huart1) != HAL_OK)
  {
    Error_Handler();
  }

}

static void MX_GPIO_Init(void)
{
  GPIO_InitTypeDef GPIO_InitStruct = {0};

  /* GPIO Ports Clock Enable */
  __HAL_RCC_GPIOE_CLK_ENABLE();
  __HAL_RCC_GPIOC_CLK_ENABLE();
  __HAL_RCC_GPIOF_CLK_ENABLE();
  __HAL_RCC_GPIOH_CLK_ENABLE();
  __HAL_RCC_GPIOA_CLK_ENABLE();
  __HAL_RCC_GPIOB_CLK_ENABLE();
  __HAL_RCC_GPIOD_CLK_ENABLE();
  __HAL_RCC_GPIOG_CLK_ENABLE();

  /*Configure GPIO pin Output Level */
  HAL_GPIO_WritePin(GPIOA, TRIG2_Pin|TRIG1_Pin|CAN2_SILENT_Pin, GPIO_PIN_RESET);

  /*Configure GPIO pin Output Level */
  HAL_GPIO_WritePin(CAN1_SILENT_GPIO_Port, CAN1_SILENT_Pin, GPIO_PIN_RESET);

  /*Configure GPIO pin Output Level */
  HAL_GPIO_WritePin(GPIOB, NRF24_CSN_Pin|LED_B_Pin, GPIO_PIN_RESET);

  /*Configure GPIO pin Output Level */
  HAL_GPIO_WritePin(GPIOD, NRF24_CE_Pin|NRF24_MODE_Pin, GPIO_PIN_RESET);

  /*Configure GPIO pin Output Level */
  HAL_GPIO_WritePin(EEPROM_WC_GPIO_Port, EEPROM_WC_Pin, GPIO_PIN_RESET);

  /*Configure GPIO pin Output Level */
  HAL_GPIO_WritePin(LED_G_GPIO_Port, LED_G_Pin, GPIO_PIN_RESET);

  /*Configure GPIO pin : MAG_DRDY_Pin */
  GPIO_InitStruct.Pin = MAG_DRDY_Pin;
  GPIO_InitStruct.Mode = GPIO_MODE_IT_RISING;
  GPIO_InitStruct.Pull = GPIO_NOPULL;
  HAL_GPIO_Init(MAG_DRDY_GPIO_Port, &GPIO_InitStruct);

  /*Configure GPIO pins : MAG_INT_Pin BTN2_Pin IMU_INT1_Pin */
  GPIO_InitStruct.Pin = MAG_INT_Pin|BTN2_Pin|IMU_INT1_Pin;
  GPIO_InitStruct.Mode = GPIO_MODE_IT_RISING;
  GPIO_InitStruct.Pull = GPIO_NOPULL;
  HAL_GPIO_Init(GPIOC, &GPIO_InitStruct);

  /*Configure GPIO pins : GPIO3_Pin GPIO4_Pin GPIO2_Pin GPIO1_Pin */
  GPIO_InitStruct.Pin = GPIO3_Pin|GPIO4_Pin|GPIO2_Pin|GPIO1_Pin;
  GPIO_InitStruct.Mode = GPIO_MODE_INPUT;
  GPIO_InitStruct.Pull = GPIO_NOPULL;
  HAL_GPIO_Init(GPIOF, &GPIO_InitStruct);

  /*Configure GPIO pin : BTN1_Pin */
  GPIO_InitStruct.Pin = BTN1_Pin;
  GPIO_InitStruct.Mode = GPIO_MODE_IT_RISING;
  GPIO_InitStruct.Pull = GPIO_NOPULL;
  HAL_GPIO_Init(BTN1_GPIO_Port, &GPIO_InitStruct);

  /*Configure GPIO pins : TRIG2_Pin TRIG1_Pin */
  GPIO_InitStruct.Pin = TRIG2_Pin|TRIG1_Pin;
  GPIO_InitStruct.Mode = GPIO_MODE_OUTPUT_PP;
  GPIO_InitStruct.Pull = GPIO_NOPULL;
  GPIO_InitStruct.Speed = GPIO_SPEED_FREQ_LOW;
  HAL_GPIO_Init(GPIOA, &GPIO_InitStruct);

  /*Configure GPIO pin : CAN2_SILENT_Pin */
  GPIO_InitStruct.Pin = CAN2_SILENT_Pin;
  GPIO_InitStruct.Mode = GPIO_MODE_OUTPUT_PP;
  GPIO_InitStruct.Pull = GPIO_PULLUP;
  GPIO_InitStruct.Speed = GPIO_SPEED_FREQ_LOW;
  HAL_GPIO_Init(CAN2_SILENT_GPIO_Port, &GPIO_InitStruct);

  /*Configure GPIO pin : CAN1_SILENT_Pin */
  GPIO_InitStruct.Pin = CAN1_SILENT_Pin;
  GPIO_InitStruct.Mode = GPIO_MODE_OUTPUT_PP;
  GPIO_InitStruct.Pull = GPIO_PULLUP;
  GPIO_InitStruct.Speed = GPIO_SPEED_FREQ_LOW;
  HAL_GPIO_Init(CAN1_SILENT_GPIO_Port, &GPIO_InitStruct);

  /*Configure GPIO pins : NRF24_CSN_Pin LED_B_Pin */
  GPIO_InitStruct.Pin = NRF24_CSN_Pin|LED_B_Pin;
  GPIO_InitStruct.Mode = GPIO_MODE_OUTPUT_PP;
  GPIO_InitStruct.Pull = GPIO_NOPULL;
  GPIO_InitStruct.Speed = GPIO_SPEED_FREQ_LOW;
  HAL_GPIO_Init(GPIOB, &GPIO_InitStruct);

  /*Configure GPIO pins : NRF24_CE_Pin NRF24_MODE_Pin */
  GPIO_InitStruct.Pin = NRF24_CE_Pin|NRF24_MODE_Pin;
  GPIO_InitStruct.Mode = GPIO_MODE_OUTPUT_PP;
  GPIO_InitStruct.Pull = GPIO_NOPULL;
  GPIO_InitStruct.Speed = GPIO_SPEED_FREQ_LOW;
  HAL_GPIO_Init(GPIOD, &GPIO_InitStruct);

  /*Configure GPIO pins : NRF24_IRQ_Pin IMU_INT2_Pin */
  GPIO_InitStruct.Pin = NRF24_IRQ_Pin|IMU_INT2_Pin;
  GPIO_InitStruct.Mode = GPIO_MODE_IT_RISING;
  GPIO_InitStruct.Pull = GPIO_NOPULL;
  HAL_GPIO_Init(GPIOD, &GPIO_InitStruct);

  /*Configure GPIO pin : EEPROM_WC_Pin */
  GPIO_InitStruct.Pin = EEPROM_WC_Pin;
  GPIO_InitStruct.Mode = GPIO_MODE_OUTPUT_PP;
  GPIO_InitStruct.Pull = GPIO_PULLUP;
  GPIO_InitStruct.Speed = GPIO_SPEED_FREQ_LOW;
  HAL_GPIO_Init(EEPROM_WC_GPIO_Port, &GPIO_InitStruct);

  /*Configure GPIO pins : PA11 PA12 */
  GPIO_InitStruct.Pin = GPIO_PIN_11|GPIO_PIN_12;
  GPIO_InitStruct.Mode = GPIO_MODE_AF_PP;
  GPIO_InitStruct.Pull = GPIO_NOPULL;
  GPIO_InitStruct.Speed = GPIO_SPEED_FREQ_LOW;
  HAL_GPIO_Init(GPIOA, &GPIO_InitStruct);

  /*Configure GPIO pins : PD6 PD7 */
  GPIO_InitStruct.Pin = GPIO_PIN_6|GPIO_PIN_7;
  GPIO_InitStruct.Mode = GPIO_MODE_AF_PP;
  GPIO_InitStruct.Pull = GPIO_NOPULL;
  GPIO_InitStruct.Speed = GPIO_SPEED_FREQ_VERY_HIGH;
  GPIO_InitStruct.Alternate = GPIO_AF11_SDMMC2;
  HAL_GPIO_Init(GPIOD, &GPIO_InitStruct);

  /*Configure GPIO pins : PG9 PG10 */
  GPIO_InitStruct.Pin = GPIO_PIN_9|GPIO_PIN_10;
  GPIO_InitStruct.Mode = GPIO_MODE_AF_PP;
  GPIO_InitStruct.Pull = GPIO_NOPULL;
  GPIO_InitStruct.Speed = GPIO_SPEED_FREQ_VERY_HIGH;
  GPIO_InitStruct.Alternate = GPIO_AF11_SDMMC2;
  HAL_GPIO_Init(GPIOG, &GPIO_InitStruct);

  /*Configure GPIO pins : PG11 PG12 */
  GPIO_InitStruct.Pin = GPIO_PIN_11|GPIO_PIN_12;
  GPIO_InitStruct.Mode = GPIO_MODE_AF_PP;
  GPIO_InitStruct.Pull = GPIO_NOPULL;
  GPIO_InitStruct.Speed = GPIO_SPEED_FREQ_VERY_HIGH;
  GPIO_InitStruct.Alternate = GPIO_AF10_SDMMC2;
  HAL_GPIO_Init(GPIOG, &GPIO_InitStruct);

  /*Configure GPIO pin : LED_G_Pin */
  GPIO_InitStruct.Pin = LED_G_Pin;
  GPIO_InitStruct.Mode = GPIO_MODE_OUTPUT_PP;
  GPIO_InitStruct.Pull = GPIO_NOPULL;
  GPIO_InitStruct.Speed = GPIO_SPEED_FREQ_LOW;
  HAL_GPIO_Init(LED_G_GPIO_Port, &GPIO_InitStruct);

  /*Configure GPIO pin : BOOT_Pin */
  GPIO_InitStruct.Pin = BOOT_Pin;
  GPIO_InitStruct.Mode = GPIO_MODE_INPUT;
  GPIO_InitStruct.Pull = GPIO_NOPULL;
  HAL_GPIO_Init(BOOT_GPIO_Port, &GPIO_InitStruct);

  /*Configure GPIO pin : SDMMC2_CD_Pin */
  GPIO_InitStruct.Pin = SDMMC2_CD_Pin;
  GPIO_InitStruct.Mode = GPIO_MODE_INPUT;
  GPIO_InitStruct.Pull = GPIO_NOPULL;
  HAL_GPIO_Init(SDMMC2_CD_GPIO_Port, &GPIO_InitStruct);

}

void startDebugTask(void *argument)
{
  for(;;)
  {
    osDelay(1);
  }
}

/* MPU Configuration */

void MPU_Config(void)
{
  MPU_Region_InitTypeDef MPU_InitStruct = {0};

  /* Disables the MPU */
  HAL_MPU_Disable();

  /** Initializes and configures the Region and the memory to be protected
  */
  MPU_InitStruct.Enable = MPU_REGION_ENABLE;
  MPU_InitStruct.Number = MPU_REGION_NUMBER0;
  MPU_InitStruct.BaseAddress = 0x0;
  MPU_InitStruct.Size = MPU_REGION_SIZE_4GB;
  MPU_InitStruct.SubRegionDisable = 0x87;
  MPU_InitStruct.TypeExtField = MPU_TEX_LEVEL0;
  MPU_InitStruct.AccessPermission = MPU_REGION_NO_ACCESS;
  MPU_InitStruct.DisableExec = MPU_INSTRUCTION_ACCESS_DISABLE;
  MPU_InitStruct.IsShareable = MPU_ACCESS_SHAREABLE;
  MPU_InitStruct.IsCacheable = MPU_ACCESS_NOT_CACHEABLE;
  MPU_InitStruct.IsBufferable = MPU_ACCESS_NOT_BUFFERABLE;

  HAL_MPU_ConfigRegion(&MPU_InitStruct);
  /* Enables the MPU */
  HAL_MPU_Enable(MPU_PRIVILEGED_DEFAULT);

}

void HAL_TIM_PeriodElapsedCallback(TIM_HandleTypeDef *htim)
{
  if (htim->Instance == TIM6) {
    HAL_IncTick();
  }
}

void Error_Handler(void)
{
  __disable_irq();
  while (1)
  {
  }
}
